AUTOSAR XML (schema 00049)
package /RTE_EVENTS_Lab
  sender receiver interface SRIF_Output
    data SumResult: type=uint32
  sender receiver interface SRIF_Input
    data Val1: type=uint16
    data Val2: type=uint16
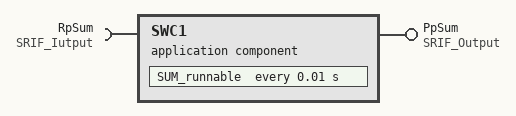
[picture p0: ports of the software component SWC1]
  application sw component type SWC1
    provide port PpSum: provided-interface=SRIF_Output
    require port RpSum: required-interface=SRIF_Iutput
    behavior SWC1_Beh
      exclusive area EXCArea1
      timing event TE_10ms: start-on-event=SUM_runnable, period=0.01
      init event InitEvent: start-on-event=SUM_runnable
      data received event DRCEvent: start-on-event=SUM_runnable, data=Val1
      data write completed event DWCEvent: start-on-event=SUM_runnable, event-source=SUMResult_Data
      runnable SUM_runnable: symbol=SUM
        data-read-access:
          access VAL1_DATA: accessed-variable=RpSum.Val1
          access VAL2_DATA: accessed-variable=RpSum.Val2
        data-write-access:
          access SUMResult_Data: accessed-variable=PpSum.SumResult
